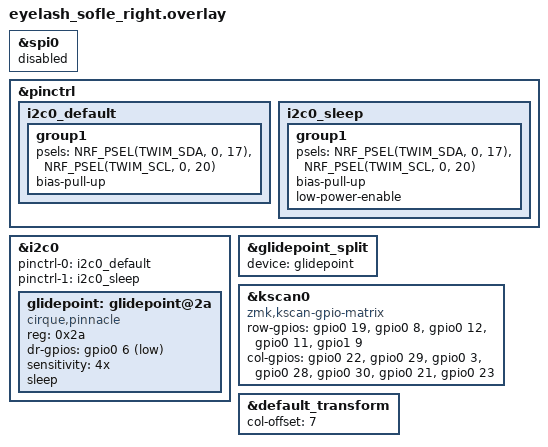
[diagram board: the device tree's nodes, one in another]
/*
 * Copyright (c) 2021 Darryl deHaan
 * SPDX-License-Identifier: MIT
 */

#include "eyelash_sofle.dtsi"
#include <behaviors/battery_history_request.dtsi>

/* Disable SPI0 to free pins P0.17, P0.20, and gpio0 6 */
&spi0 {
    status = "disabled";
};

/* Set up software pull-ups on I2C lines */
&pinctrl {
    i2c0_default: i2c0_default {
        group1 {
            psels = <NRF_PSEL(TWIM_SDA, 0, 17)>,
                    <NRF_PSEL(TWIM_SCL, 0, 20)>;
            bias-pull-up;
        };
    };

    i2c0_sleep: i2c0_sleep {
        group1 {
            psels = <NRF_PSEL(TWIM_SDA, 0, 17)>,
                    <NRF_PSEL(TWIM_SCL, 0, 20)>;
            bias-pull-up;
            low-power-enable;
        };
    };
};

/* Initialize I2C and Cirque Trackpad */
&i2c0 {
    status = "okay";
    pinctrl-0 = <&i2c0_default>;
    pinctrl-1 = <&i2c0_sleep>;
    pinctrl-names = "default", "sleep";

    glidepoint: glidepoint@2a {
        compatible = "cirque,pinnacle";
        reg = <0x2a>;
        status = "okay";
        dr-gpios = <&gpio0 6 (GPIO_ACTIVE_LOW | GPIO_PULL_UP)>;
        sensitivity = "4x";
        sleep;
    };
};

/* Route trackpad data to the split transmitter */
&glidepoint_split {
    status = "okay";
    device = <&glidepoint>;
};

/* Matrix definition for right half */
&kscan0 {
    compatible = "zmk,kscan-gpio-matrix";
    row-gpios
        = <&gpio0 19 (GPIO_ACTIVE_HIGH | GPIO_PULL_DOWN)>
        , <&gpio0 8 (GPIO_ACTIVE_HIGH | GPIO_PULL_DOWN)>
        , <&gpio0 12 (GPIO_ACTIVE_HIGH | GPIO_PULL_DOWN)>
        , <&gpio0 11 (GPIO_ACTIVE_HIGH | GPIO_PULL_DOWN)>
        , <&gpio1 9 (GPIO_ACTIVE_HIGH | GPIO_PULL_DOWN)>
        ;
    col-gpios
        = <&gpio0 22 GPIO_ACTIVE_HIGH>
        , <&gpio0 29 GPIO_ACTIVE_HIGH>
        , <&gpio0 3 GPIO_ACTIVE_HIGH>
        , <&gpio0 28 GPIO_ACTIVE_HIGH>
        , <&gpio0 30 GPIO_ACTIVE_HIGH>
        , <&gpio0 21 GPIO_ACTIVE_HIGH>
        , <&gpio0 23 GPIO_ACTIVE_HIGH>
        ;
};

&default_transform {
    col-offset = <7>;
};
